# PIC32CX1012BZ25048 register map
Vendor: Microchip Technology; Series: BZ25; File version: 0
CPU: CM4 r0p1, little endian, MPU, FPU, 3 interrupt priority bits
Registers are 32-bit, read-write, reset 0x0 unless marked. A register's access mark holds for its fields unless they carry their own. Offsets are from the block's base; [hi:lo] are bit positions.

## SysTick — System timer
Base 0xE000E010; register names take the prefix SysTick_
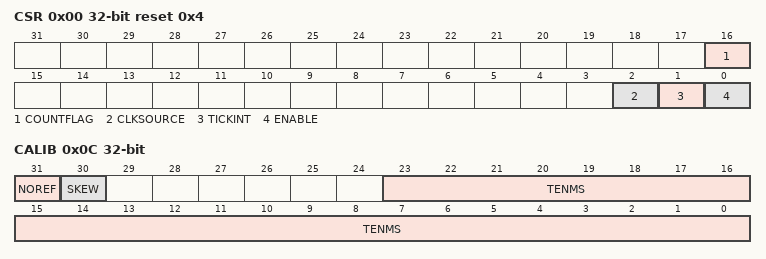
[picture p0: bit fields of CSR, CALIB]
0x00 CSR reset 0x4 — SysTick Control and Status Register
  [16] COUNTFLAG — Timer counted to 0 since last read of register
  [2] CLKSOURCE — Clock Source 0=external, 1=processor
    0=External clock; 1=Processor clock
  [1] TICKINT — SysTick Exception Request Enable
    0=Counting down to 0 does not assert the SysTick exception request; 1=Counting down to 0 asserts the SysTick exception request
  [0] ENABLE — SysTick Counter Enable
    0=Counter disabled; 1=Counter enabled
0x04 RVR — SysTick Reload Value Register
  [23:0] RELOAD — Value to load into the SysTick Current Value Register when the counter reaches 0
0x08 CVR — SysTick Current Value Register
  [23:0] CURRENT — Current value at the time the register is accessed
0x0C CALIB ro — SysTick Calibration Value Register
  [31] NOREF — No Separate Reference Clock
    0=The reference clock is provided; 1=The reference clock is not provided
  [30] SKEW — TENMS is rounded from non-integer ratio
    0=10ms calibration value is exact; 1=10ms calibration value is inexact, because of the clock frequency
  [23:0] TENMS — Reload value to use for 10ms timing

## TPI — Trace Port Interface Register
Base 0xE0040000; register names take the prefix TPI_
0x00 SSPSR ro — Supported Parallel Port Size Register
0x04 CSPSR — Current Parallel Port Size Register
0x10 ACPR — Asynchronous Clock Prescaler Register
  [12:0] PRESCALER
0xF0 SPPR — Selected Pin Protocol Register
  [1:0] TXMODE
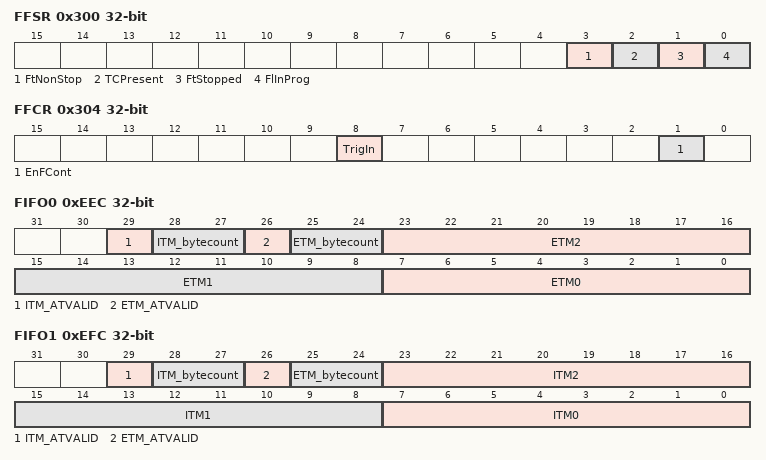
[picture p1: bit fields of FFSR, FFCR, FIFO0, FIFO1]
0x300 FFSR ro — Formatter and Flush Status Register
  [3] FtNonStop, [2] TCPresent, [1] FtStopped, [0] FlInProg
0x304 FFCR — Formatter and Flush Control Register
  [8] TrigIn, [1] EnFCont
0x308 FSCR ro — Formatter Synchronization Counter Register
0xEE8 TRIGGER ro
  [0] TRIGGER
0xEEC FIFO0 ro — Integration ETM Data
  [29] ITM_ATVALID, [28:27] ITM_bytecount, [26] ETM_ATVALID, [25:24] ETM_bytecount, [23:16] ETM2, [15:8] ETM1, [7:0] ETM0
0xEF0 ITATBCTR2 ro
  [0] ATREADY
0xEF8 ITATBCTR0 ro
  [0] ATREADY
0xEFC FIFO1 ro — Integration ITM Data
  [29] ITM_ATVALID, [28:27] ITM_bytecount, [26] ETM_ATVALID, [25:24] ETM_bytecount, [23:16] ITM2, [15:8] ITM1, [7:0] ITM0
0xF00 ITCTRL — Integration Mode Control
  [0] Mode
0xFA0 CLAIMSET — Claim tag set
0xFA4 CLAIMCLR — Claim tag clear
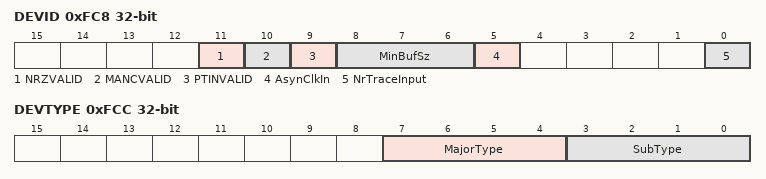
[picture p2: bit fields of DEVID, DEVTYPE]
0xFC8 DEVID ro — TPIU_DEVID
  [11] NRZVALID, [10] MANCVALID, [9] PTINVALID, [8:6] MinBufSz, [5] AsynClkIn, [0] NrTraceInput
0xFCC DEVTYPE ro — TPIU_DEVTYPE
  [7:4] MajorType, [3:0] SubType

## ZIGBEE — ZIGBEE Radio Registers
Base 0x41010000; register names take the prefix ZIGBEE_

## ARB — Radio Arbiter
Base 0x41011000; register names take the prefix ARB_
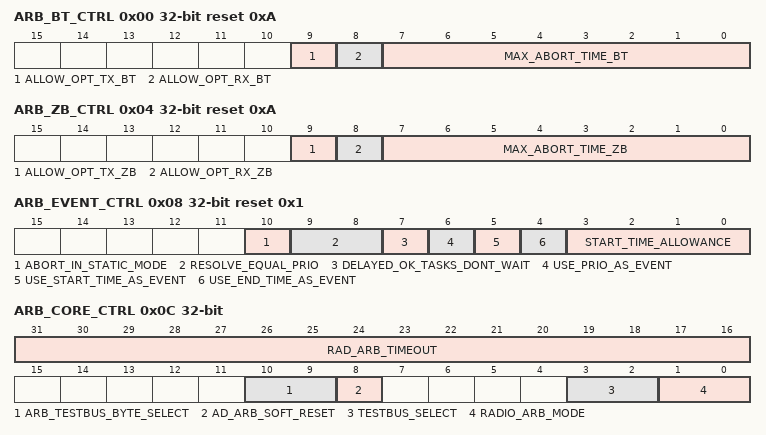
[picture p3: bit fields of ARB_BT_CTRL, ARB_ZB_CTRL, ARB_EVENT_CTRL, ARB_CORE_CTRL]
0x00 ARB_BT_CTRL reset 0xA
  [9] ALLOW_OPT_TX_BT — BT allow optimistic tx
  [8] ALLOW_OPT_RX_BT — BT allow optimistic rx
  [7:0] MAX_ABORT_TIME_BT — BT max abort time
0x04 ARB_ZB_CTRL reset 0xA
  [9] ALLOW_OPT_TX_ZB — ZB allow optimistic tx
  [8] ALLOW_OPT_RX_ZB — ZB allow optimistic rx
  [7:0] MAX_ABORT_TIME_ZB — ZB max abort time
0x08 ARB_EVENT_CTRL reset 0x1
  [10] ABORT_IN_STATIC_MODE
  [9:8] RESOLVE_EQUAL_PRIO
  [7] DELAYED_OK_TASKS_DONT_WAIT
  [6] USE_PRIO_AS_EVENT
  [5] USE_START_TIME_AS_EVENT
  [4] USE_END_TIME_AS_EVENT
  [3:0] START_TIME_ALLOWANCE — minimum change needed in the start time to be considered as an arbitration event.
0x0C ARB_CORE_CTRL
  [31:16] RAD_ARB_TIMEOUT, [10:9] ARB_TESTBUS_BYTE_SELECT, [8] AD_ARB_SOFT_RESET, [3:2] TESTBUS_SELECT, [1:0] RADIO_ARB_MODE
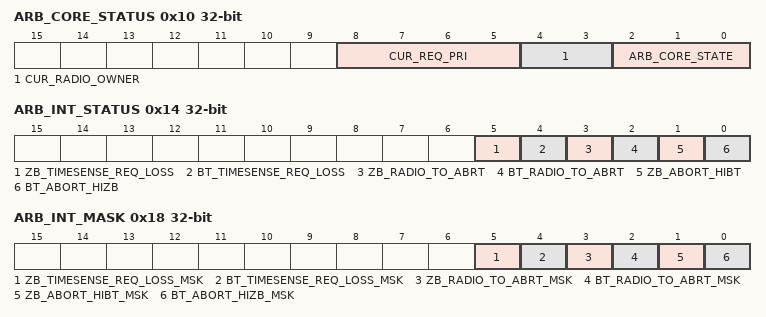
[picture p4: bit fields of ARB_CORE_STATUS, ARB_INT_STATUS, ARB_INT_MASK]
0x10 ARB_CORE_STATUS ro
  [8:5] CUR_REQ_PRI, [4:3] CUR_RADIO_OWNER, [2:0] ARB_CORE_STATE
0x14 ARB_INT_STATUS
  [5] ZB_TIMESENSE_REQ_LOSS, [4] BT_TIMESENSE_REQ_LOSS, [3] ZB_RADIO_TO_ABRT, [2] BT_RADIO_TO_ABRT, [1] ZB_ABORT_HIBT, [0] BT_ABORT_HIZB
0x18 ARB_INT_MASK
  [5] ZB_TIMESENSE_REQ_LOSS_MSK, [4] BT_TIMESENSE_REQ_LOSS_MSK, [3] ZB_RADIO_TO_ABRT_MSK, [2] BT_RADIO_TO_ABRT_MSK, [1] ZB_ABORT_HIBT_MSK, [0] BT_ABORT_HIZB_MSK
